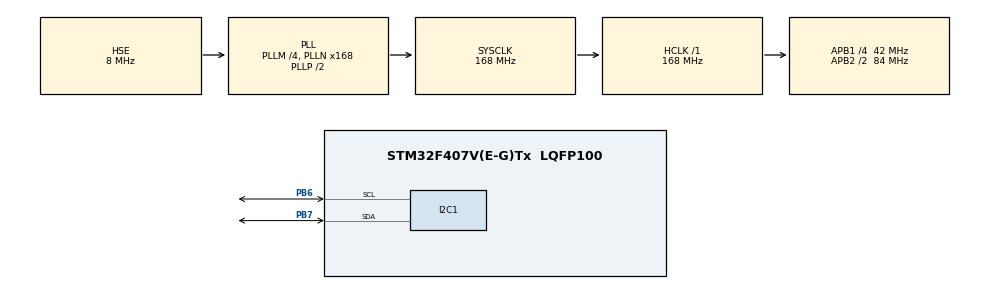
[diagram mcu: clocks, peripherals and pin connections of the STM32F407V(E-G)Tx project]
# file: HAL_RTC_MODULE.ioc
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Mcu.Family=STM32F4
Mcu.Name=STM32F407V(E-G)Tx
Mcu.Package=LQFP100
NVIC.PriorityGroup=NVIC_PRIORITYGROUP_4
PB6.Mode=I2C
PB6.Signal=I2C1_SCL
PB7.Mode=I2C
PB7.Signal=I2C1_SDA
PH0-OSC_IN.Mode=HSE-External-Oscillator
PH0-OSC_IN.Signal=RCC_OSC_IN
PH1-OSC_OUT.Mode=HSE-External-Oscillator
PH1-OSC_OUT.Signal=RCC_OSC_OUT
ProjectManager.HeapSize=0x200
ProjectManager.StackSize=0x400
ProjectManager.TargetToolchain=STM32CubeIDE
RCC.48MHZClocksFreq_Value=84000000
RCC.AHBFreq_Value=168000000
RCC.APB1CLKDivider=RCC_HCLK_DIV4
RCC.APB1Freq_Value=42000000
RCC.APB1TimFreq_Value=84000000
RCC.APB2CLKDivider=RCC_HCLK_DIV2
RCC.APB2Freq_Value=84000000
RCC.APB2TimFreq_Value=168000000
RCC.CortexFreq_Value=168000000
RCC.HCLKFreq_Value=168000000
RCC.HSE_VALUE=8000000
RCC.HSI_VALUE=16000000
RCC.LSE_VALUE=32768
RCC.PLLM=4
RCC.PLLN=168
RCC.PLLSourceVirtual=RCC_PLLSOURCE_HSE
RCC.RCC_RTC_Clock_Source=RCC_RTCCLKSOURCE_HSE_DIV20
RCC.RCC_RTC_Clock_Source_FROM_HSE=RCC_RTCCLKSOURCE_HSE_DIV20
RCC.SYSCLKFreq_VALUE=168000000
RCC.SYSCLKSource=RCC_SYSCLKSOURCE_PLLCLK
RCC.VCOOutputFreq_Value=336000000
RTC.AsynchPrediv=99
RTC.Date=27
RTC.Format=RTC_FORMAT_BIN
RTC.Hours=14
RTC.Minutes=32
RTC.Month=RTC_MONTH_AUGUST
RTC.SynchPrediv=3999
RTC.WeekDay=RTC_WEEKDAY_TUESDAY
RTC.Year=24
VP_RTC_VS_RTC_Activate.Mode=RTC_Enabled
VP_RTC_VS_RTC_Calendar.Mode=RTC_Calendar
board=custom

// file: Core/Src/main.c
/* USER CODE BEGIN Header */
/**
  ******************************************************************************
  * @file           : main.c
  * @brief          : Main program body
  ******************************************************************************
  * @attention
  *
  * Copyright (c) 2024 STMicroelectronics.
  * All rights reserved.
  *
  * This software is licensed under terms that can be found in the LICENSE file
  * in the root directory of this software component.
  * If no LICENSE file comes with this software, it is provided AS-IS.
  *
  ******************************************************************************
  */
/* USER CODE END Header */
#include "main.h"

/* USER CODE BEGIN Includes */
#include "ssd1306_conf_template.h"
#include "ssd1306.h"
#include "ssd1306_fonts.h"
#include "stdio.h"
#include <string.h>
/* USER CODE END Includes */

I2C_HandleTypeDef hi2c1;

RTC_HandleTypeDef hrtc;

void SystemClock_Config(void);
static void MX_GPIO_Init(void);
static void MX_RTC_Init(void);
static void MX_I2C1_Init(void);

/* USER CODE BEGIN 0 */

/*
 Coder's Note:
 Usually the LSE clock is used for rtc application for more precise results.
 But the LSE clock on my board is not operational due to undetermined reasons
 HSE clock is used for the application. The RTC frequency is set 400KHz.
 ck_spre = 1 =(RTC_Frequency) / ( (AsynchPrediv+1)x(SynchPrediv+1) );
AsynchPrediv=99, SynchPrediv=3999
 */

/* Global variables */
uint8_t day, month, year, second, minute, hour;
char time[15], date[15];

/**
 * @brief Retrieves the current time from the RTC and assigns it to global variables.
 */
void get_rtc_time()
{
    RTC_TimeTypeDef sTime = {0};

    // Get the current time from the RTC
    HAL_RTC_GetTime(&hrtc, &sTime, RTC_FORMAT_BIN);

    // Assign the retrieved time to global variables
    second = sTime.Seconds;
    minute = sTime.Minutes;
    hour = sTime.Hours;
}

/**
 * @brief Retrieves the current date from the RTC and assigns it to global variables.
 */
void get_rtc_date()
{
    RTC_DateTypeDef sDate;

    // Get the current date from the RTC
    HAL_RTC_GetDate(&hrtc, &sDate, RTC_FORMAT_BIN);

    // Assign the retrieved date to global variables
    day = sDate.Date;
    month = sDate.Month;
    year = sDate.Year;
}

/**
 * @brief Displays the time and date on the OLED screen.
 */
void oled_display()
{
    // Format the time and store it in the time array
    sprintf(time, "%02u:%02u:%02u", hour, minute, second);

    // Display the time on the OLED screen
    ssd1306_SetCursor(30, 20);
    ssd1306_WriteString(time, Font_7x10, Black);
    ssd1306_UpdateScreen();

    // Format the date and store it in the date array
    sprintf(date, "%02u:%02u:20%02u", day, month, year);

    // Display the date on the OLED screen
    ssd1306_SetCursor(30, 35);
    ssd1306_WriteString(date, Font_7x10, Black);
    ssd1306_UpdateScreen();
}

/* USER CODE END 0 */

int main(void)
{

  /* MCU Configuration--------------------------------------------------------*/

  /* Reset of all peripherals, Initializes the Flash interface and the Systick. */
  HAL_Init();

  /* Configure the system clock */
  SystemClock_Config();

  /* Initialize all configured peripherals */
  MX_GPIO_Init();
  MX_RTC_Init();
  MX_I2C1_Init();
  /* USER CODE BEGIN 2 */
  ssd1306_Init();
  ssd1306_Fill(White);
  ssd1306_UpdateScreen();
  /* USER CODE END 2 */

  /* Infinite loop */
  while (1)
  {

    /* USER CODE BEGIN 3 */
	  get_rtc_time();
	  get_rtc_date();
	  oled_display();
  }
  /* USER CODE END 3 */
}

void SystemClock_Config(void)
{
  RCC_OscInitTypeDef RCC_OscInitStruct = {0};
  RCC_ClkInitTypeDef RCC_ClkInitStruct = {0};

  /** Configure the main internal regulator output voltage
  */
  __HAL_RCC_PWR_CLK_ENABLE();
  __HAL_PWR_VOLTAGESCALING_CONFIG(PWR_REGULATOR_VOLTAGE_SCALE1);

  /** Initializes the RCC Oscillators according to the specified parameters
  * in the RCC_OscInitTypeDef structure.
  */
  RCC_OscInitStruct.OscillatorType = RCC_OSCILLATORTYPE_HSE;
  RCC_OscInitStruct.HSEState = RCC_HSE_ON;
  RCC_OscInitStruct.PLL.PLLState = RCC_PLL_ON;
  RCC_OscInitStruct.PLL.PLLSource = RCC_PLLSOURCE_HSE;
  RCC_OscInitStruct.PLL.PLLM = 4;
  RCC_OscInitStruct.PLL.PLLN = 168;
  RCC_OscInitStruct.PLL.PLLP = RCC_PLLP_DIV2;
  RCC_OscInitStruct.PLL.PLLQ = 4;
  if (HAL_RCC_OscConfig(&RCC_OscInitStruct) != HAL_OK)
  {
    Error_Handler();
  }

  /** Initializes the CPU, AHB and APB buses clocks
  */
  RCC_ClkInitStruct.ClockType = RCC_CLOCKTYPE_HCLK|RCC_CLOCKTYPE_SYSCLK
                              |RCC_CLOCKTYPE_PCLK1|RCC_CLOCKTYPE_PCLK2;
  RCC_ClkInitStruct.SYSCLKSource = RCC_SYSCLKSOURCE_PLLCLK;
  RCC_ClkInitStruct.AHBCLKDivider = RCC_SYSCLK_DIV1;
  RCC_ClkInitStruct.APB1CLKDivider = RCC_HCLK_DIV4;
  RCC_ClkInitStruct.APB2CLKDivider = RCC_HCLK_DIV2;

  if (HAL_RCC_ClockConfig(&RCC_ClkInitStruct, FLASH_LATENCY_5) != HAL_OK)
  {
    Error_Handler();
  }
}

static void MX_I2C1_Init(void)
{

  hi2c1.Instance = I2C1;
  hi2c1.Init.ClockSpeed = 100000;
  hi2c1.Init.DutyCycle = I2C_DUTYCYCLE_2;
  hi2c1.Init.OwnAddress1 = 0;
  hi2c1.Init.AddressingMode = I2C_ADDRESSINGMODE_7BIT;
  hi2c1.Init.DualAddressMode = I2C_DUALADDRESS_DISABLE;
  hi2c1.Init.OwnAddress2 = 0;
  hi2c1.Init.GeneralCallMode = I2C_GENERALCALL_DISABLE;
  hi2c1.Init.NoStretchMode = I2C_NOSTRETCH_DISABLE;
  if (HAL_I2C_Init(&hi2c1) != HAL_OK)
  {
    Error_Handler();
  }

}

static void MX_RTC_Init(void)
{

  RTC_TimeTypeDef sTime = {0};
  RTC_DateTypeDef sDate = {0};

  /** Initialize RTC Only
  */
  hrtc.Instance = RTC;
  hrtc.Init.HourFormat = RTC_HOURFORMAT_24;
  hrtc.Init.AsynchPrediv = 99;
  hrtc.Init.SynchPrediv = 3999;
  hrtc.Init.OutPut = RTC_OUTPUT_DISABLE;
  hrtc.Init.OutPutPolarity = RTC_OUTPUT_POLARITY_HIGH;
  hrtc.Init.OutPutType = RTC_OUTPUT_TYPE_OPENDRAIN;
  if (HAL_RTC_Init(&hrtc) != HAL_OK)
  {
    Error_Handler();
  }

  /** Initialize RTC and set the Time and Date
  */
  sTime.Hours = 14;
  sTime.Minutes = 32;
  sTime.Seconds = 0;
  sTime.DayLightSaving = RTC_DAYLIGHTSAVING_NONE;
  sTime.StoreOperation = RTC_STOREOPERATION_RESET;
  if (HAL_RTC_SetTime(&hrtc, &sTime, RTC_FORMAT_BIN) != HAL_OK)
  {
    Error_Handler();
  }
  sDate.WeekDay = RTC_WEEKDAY_TUESDAY;
  sDate.Month = RTC_MONTH_AUGUST;
  sDate.Date = 27;
  sDate.Year = 24;

  if (HAL_RTC_SetDate(&hrtc, &sDate, RTC_FORMAT_BIN) != HAL_OK)
  {
    Error_Handler();
  }

}

static void MX_GPIO_Init(void)
{

  /* GPIO Ports Clock Enable */
  __HAL_RCC_GPIOH_CLK_ENABLE();
  __HAL_RCC_GPIOB_CLK_ENABLE();

}

void Error_Handler(void)
{
  __disable_irq();
  while (1)
  {
  }
}
